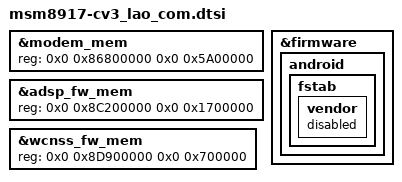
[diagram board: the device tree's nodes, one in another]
/*
 * Copyright (c) 2016, The Linux Foundation. All rights reserved.
 *
 * This program is free software; you can redistribute it and/or modify
 * it under the terms of the GNU General Public License version 2 and
 * only version 2 as published by the Free Software Foundation.
 *
 * This program is distributed in the hope that it will be useful,
 * but WITHOUT ANY WARRANTY; without even the implied warranty of
 * MERCHANTABILITY or FITNESS FOR A PARTICULAR PURPOSE.  See the
 * GNU General Public License for more details.
 */

#include "msm8917-cv3_lao_com-pinctrl.dtsi"
#include "msm8917-cv3_lao_com-camera.dtsi"
#include "msm8917-cv3_lao_com-panel.dtsi"
#include "msm8917-cv3_lao_com-sound.dtsi"
#include "msm8917-cv3_lao_com-misc.dtsi"
#include "msm8917-cv3_lao_com-pm.dtsi"
#include "msm8917-cv3_lao_com-touch.dtsi"
#include "msm8917-cv3_lao_com-fingerprint.dtsi"
#include "msm8917-cv3_lao_com-nfc.dtsi"

&modem_mem {
	reg = <0x0 0x86800000 0x0 0x5A00000>;
};

&adsp_fw_mem {
	reg = <0x0 0x8C200000 0x0 0x1700000>;
};

&wcnss_fw_mem {
	reg = <0x0 0x8D900000 0x0 0x700000>;
};

&firmware {
	android {
		fstab {
			vendor {
				status = "disabled";
			};
		};
	};
};
